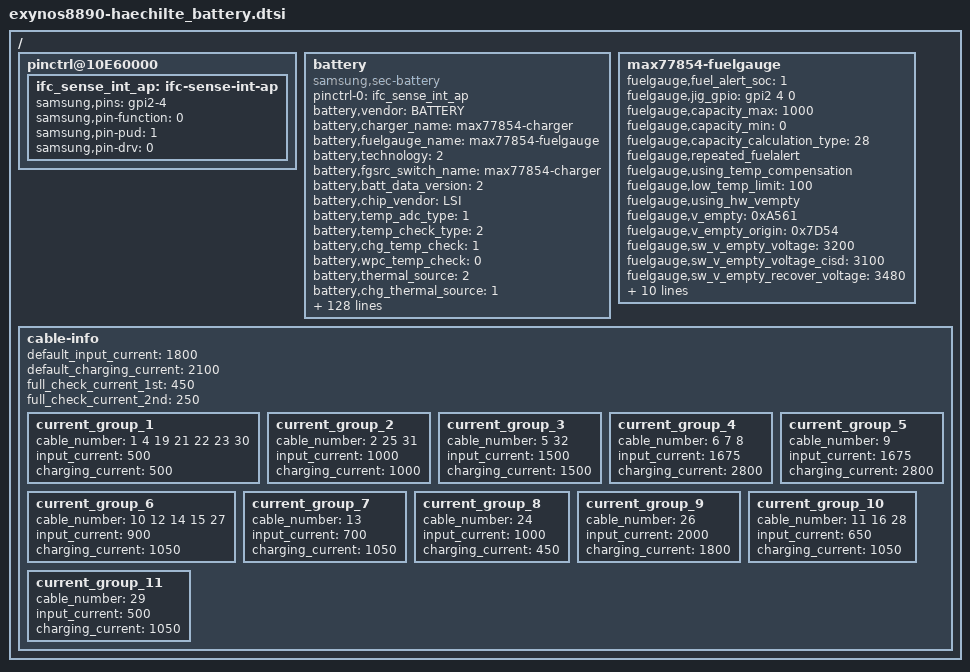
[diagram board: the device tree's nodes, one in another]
/*
 * SAMSUNG UNIVERSAL5433 board device tree source
 *
 * Copyright (c) 2013 Samsung Electronics Co., Ltd.
 *		http://www.samsung.com
 *
 * This program is free software; you can redistribute it and/or modify
 * it under the terms of the GNU General Public License version 2 as
 * published by the Free Software Foundation.
*/

/ {
	pinctrl@10E60000 {

		ifc_sense_int_ap: ifc-sense-int-ap {
			samsung,pins = "gpi2-4";
			samsung,pin-function = <0>;
			samsung,pin-pud = <1>;
			samsung,pin-drv = <0>;
		};
	};
	battery {
		status = "okay";
		compatible = "samsung,sec-battery";

		pinctrl-names = "default";
		pinctrl-0 = <&ifc_sense_int_ap>;
		/* battery,irq_gpio = <&gpa1 6 0>; */

		battery,vendor = "BATTERY";
		battery,charger_name = "max77854-charger";
		battery,fuelgauge_name = "max77854-fuelgauge";
		battery,technology = <2>; /* POWER_SUPPLY_TECHNOLOGY_LION */
		battery,fgsrc_switch_name = "max77854-charger"; /* Fuelgauge voltage source */

		battery,batt_data_version = <2>;

		battery,chip_vendor = "LSI";
		battery,temp_adc_type = <1>; /* SEC_BATTERY_ADC_TYPE_AP */

		battery,temp_check_type = <2>; /* SEC_BATTERY_TEMP_CHECK_TEMP */
		battery,chg_temp_check = <1>;
		battery,wpc_temp_check = <0>;

		battery,thermal_source = <2>; /* SEC_BATTERY_THERMAL_SOURCE_ADC */
		battery,chg_thermal_source = <1>; /* true or false */
		battery,wpc_thermal_source = <0>; /* true or false */
		battery,usb_thermal_source = <0>; /* true or false */
		battery,coil_thermal_source = <0>; /* true or false */

		battery,polling_time = <10 30 30 30 3600>;

		battery,temp_table_adc = <316 359 410 558 611 759 880 1023 1201 1368 1553 1790 2234 2726 2932 3128 3294 3442 3666>;
		battery,temp_table_data = <900 850 800 700 650 600 550 500 450 400 350 300 200 100 50 0 (-50) (-100) (-200)>;

		battery,chg_temp_table_adc = <307 351 405 511 647 758 885 1031 1208 1363 1549 1792 2224 2738 2941 3135 3299 3455 3672>;
		battery,chg_temp_table_data = <900 850 800 700 650 600 550 500 450 400 350 300 200 100 50 0 (-50) (-100) (-200)>;

		battery,wireless_cc_cv = <85>;
		battery,inbat_voltage = <1>;
		battery,inbat_voltage_table_adc = <3120 3101 3061 3038 3001 2956 2920 2887 2856 2814
						2793 2754 2720 2677 2641 2613 2572 2531 2502 2467 2436>;
		battery,inbat_voltage_table_data = <438 435 430 425 420 415 410 405 400 395
						390 385 380 375 370 365 360 355 350 345 340>;

		battery,adc_check_count = <5>;

		battery,cable_check_type = <4>; /* SEC_BATTERY_CABLE_CHECK_PSY */
		battery,cable_source_type = <1>; /* SEC_BATTERY_CABLE_SOURCE_EXTERNAL */
		battery,polling_type = <1>; /* SEC_BATTERY_MONITOR_ALARM */
		battery,monitor_initial_count = <0>;

		battery,battery_check_type = <5>; /* SEC_BATTERY_CHECK_CHARGER */
		battery,check_count = <0>;
		battery,check_adc_max = <1440>;
		battery,check_adc_min = <0>;

		battery,ovp_uvlo_check_type = <3>; /* SEC_BATTERY_OVP_UVLO_CHGPOLLING */

		battery,temp_check_count = <1>;
		battery,temp_highlimit_threshold_event = <800>;
		battery,temp_highlimit_recovery_event = <750>;
		battery,temp_high_threshold_event = <500>;
		battery,temp_high_recovery_event = <450>;
		battery,temp_low_threshold_event = <0>;
		battery,temp_low_recovery_event = <50>;
		battery,temp_highlimit_threshold_normal = <800>;
		battery,temp_highlimit_recovery_normal = <750>;
		battery,temp_high_threshold_normal = <500>;
		battery,temp_high_recovery_normal = <450>;
		battery,temp_low_threshold_normal = <0>;
		battery,temp_low_recovery_normal = <50>;
		battery,temp_highlimit_threshold_lpm = <800>;
		battery,temp_highlimit_recovery_lpm = <750>;
		battery,temp_high_threshold_lpm = <500>;
		battery,temp_high_recovery_lpm = <450>;
		battery,temp_low_threshold_lpm = <0>;
		battery,temp_low_recovery_lpm = <50>;
		battery,full_check_type = <7>; /* SEC_BATTERY_FULLCHARGED_CHGPSY */
		battery,full_check_type_2nd = <7>; /* SEC_BATTERY_FULLCHARGED_CHGPSY */
		battery,full_check_count = <1>;
		battery,chg_gpio_full_check = <0>;
		battery,chg_polarity_full_check = <1>;

		battery,chg_high_temp = <430>; /* EUR use eur_xx.dtsi */
		battery,chg_high_temp_recovery = <380>; /* EUR use eur_xx.dtsi */
		battery,chg_input_limit_current = <1100>;
		battery,chg_charging_limit_current = <2800>;

		battery,sleep_mode_limit_current = <500>;
		battery,wc_full_input_limit_current = <100>;
		battery,wc_cv_current = <820>;

		battery,mix_high_temp = <430>;
		battery,mix_high_chg_temp = <530>;
		battery,mix_high_temp_recovery = <400>;

		/* SEC_BATTERY_FULL_CONDITION_NOTIMEFULL |
		   SEC_BATTERY_FULL_CONDITION_VCELL */
		battery,full_condition_type = <9>;
		battery,full_condition_soc = <93>;
		battery,full_condition_vcell = <4125>;

		battery,recharge_check_count = <1>;
		battery,recharge_condition_type = <4>; /* SEC_BATTERY_RECHARGE_CONDITION_VCELL */
		battery,recharge_condition_soc = <98>;
		battery,recharge_condition_vcell = <4125>;

		battery,charging_total_time = <14400>;
		battery,hv_charging_total_time = <10800>;
		battery,normal_charging_total_time = <18000>;
		battery,usb_charging_total_time = <36000>;
		battery,recharging_total_time = <5400>;
		battery,charging_reset_time = <0>;

		battery,chg_float_voltage = <42250>;
		battery,chg_float_voltage_conv = <10>;

		battery,wa_volt_recov = <4065>;
		battery,wa_volt_thr = <4075>;
		battery,wa_float_voltage = <40500>;

		battery,swelling_high_temp_block = <410>;
		battery,swelling_high_temp_recov = <390>;
		battery,swelling_low_temp_block_1st = <150>;
		battery,swelling_low_temp_recov_1st = <200>;
		battery,swelling_low_temp_block_2nd = <50>;
		battery,swelling_low_temp_recov_2nd = <100>;

		battery,swelling_low_temp_current = <1050>;	/* 0.3C */
		battery,swelling_low_temp_topoff = <250>;	/* 0.05C */
		battery,swelling_high_temp_current = <1600>;	/* 0.45C */
		battery,swelling_high_temp_topoff = <250>;	/* 0.05C */
		battery,swelling_wc_high_temp_current = <1050>;	/* 0.3C */
		battery,swelling_wc_low_temp_current = <1050>;	/* 0.3C */

		battery,swelling_drop_float_voltage = <41000>;
		battery,swelling_high_rechg_voltage = <3900>;
		battery,swelling_low_rechg_voltage = <3900>;

		battery,siop_event_check_type = <1>;
		battery,siop_call_cv_current = <330>;
		battery,siop_call_cc_current = <330>;

		battery,siop_input_limit_current = <1200>;
		battery,siop_charging_limit_current = <1000>;
		battery,siop_hv_input_limit_current = <700>;
		battery,siop_hv_charging_limit_current = <1000>;

		battery,siop_wireless_input_limit_current = <600>;
		battery,siop_wireless_charging_limit_current = <1000>;
		battery,siop_hv_wireless_input_limit_current = <600>;
		battery,siop_hv_wireless_charging_limit_current = <1000>;

		battery,ttf_hv_charge_current = <2800>;
		battery,ttf_hv_wireless_charge_current = <1500>;

		battery,pd_charging_charge_power = <15000>;
		battery,max_charging_current = <2800>;
		battery,battery_full_capacity = <4500>;

		battery,factory_store_mode_max = <70>;
		battery,factory_store_mode_min = <60>;

		/* cycle(week), chg_float_voltage, recharge_condition_vcell, full_condition_vcell, full_condition_soc, max_charging_current(B2B) */
		battery,age_data = <0 42250 4125 4125 93 2800
			70 41875 4087 4087 91 2500
			140 41625 4062 4062 89 2150>;

		battery,max_input_voltage = <12000>; /* mV */
		battery,max_input_current = <3000>;  /* mA */

		battery,enable_sysovlo_irq;

		battery,standard_curr = <2800>;
		battery,expired_time = <13380>;
		battery,recharging_expired_time = <5400>;

		battery,cisd_max_voltage_thr = <4400>; /* battery ovp detection voltage */

		io-channels = <&exynos_adc 1>, <&exynos_adc 3>, <&exynos_adc 6>;
		io-channel-names = "adc-temp", "adc-chg-temp", "adc-in-bat";
		#io-channel-cells = <3>;
		io-channel-ranges;
	};

	max77854-fuelgauge {
		status = "okay";
		fuelgauge,fuel_alert_soc = <1>;
		fuelgauge,jig_gpio = <&gpi2 4 0>;
		fuelgauge,capacity_max = <1000>;

		fuelgauge,capacity_min = <0>;
		fuelgauge,capacity_calculation_type = <28>;
		fuelgauge,repeated_fuelalert;
		fuelgauge,using_temp_compensation;
		fuelgauge,low_temp_limit = <100>;
		fuelgauge,using_hw_vempty;
		fuelgauge,v_empty = <0xA561>; /* Empty: 3260mV, Recover: 3480mV */
		fuelgauge,v_empty_origin = <0x7D54>; /* Empty: 2500mV, Recover: 3360mV */
		fuelgauge,sw_v_empty_voltage = <3200>;
		fuelgauge,sw_v_empty_voltage_cisd = <3100>;
		fuelgauge,sw_v_empty_recover_voltage = <3480>;
		fuelgauge,qrtable20 = <0x0901>;
		fuelgauge,qrtable30 = <0x0803>;
		fuelgauge,dpacc = <0x3200>;
		fuelgauge,dqacc = <0x07BB>;
		fuelgauge,fg_resistor = <1>;
		fuelgauge,capacity = <0x1EED>;
		/*fuelgauge,auto_discharge_en;*/
		fuelgauge,discharge_temp_threshold = <600>;
		fuelgauge,discharge_volt_threshold = <4540>;
		fuelgauge,cv_data = <2480	687	3450
			2462	693	3420
			2442	699	3389
			2421	704	3360
			2401	710	3329
			2379	715	3300
			2357	721	3269
			2338	726	3240
			2316	731	3209
			2294	737	3181
			2272	742	3150
			2248	747	3121
			2225	752	3090
			2202	757	3060
			2180	762	3029
			2156	767	3000
			2133	772	2969
			2132	773	2940
			2110	777	2909
			2086	782	2905
			2064	786	2881
			2035	791	2850
			2016	795	2820
			1991	800	2789
			1967	802	2760
			1945	804	2729
			1919	808	2700
			1895	812	2669
			1873	817	2640
			1850	821	2609
			1826	825	2581
			1801	829	2550
			1781	833	2520
			1759	837	2489
			1738	841	2460
			1716	844	2429
			1695	848	2401
			1672	852	2370
			1650	856	2340
			1628	859	2309
			1607	863	2280
			1585	866	2249
			1565	870	2220
			1543	873	2189
			1520	875	2160
			1498	877	2129
			1475	880	2099
			1455	882	2068
			1450	884	2040
			1409	887	2009
			1383	891	1981
			1360	893	1950
			1336	896	1920
			1313	899	1889
			1290	902	1860
			1279	905	1829
			1228	908	1800
			1205	911	1769
			1185	913	1740
			1162	916	1709
			1140	918	1680
			1118	921	1649
			1098	923	1620
			1077	926	1589
			1059	928	1560
			1041	930	1529
			1024	931	1501
			1006	933	1470
			990	935	1439
			975	937	1409
			960	939	1380
			946	940	1349
			931	941	1321
			914	943	1290
			903	945	1260
			895	946	1229
			876	947	1199
			867	949	1168
			866	950	1140
			851	951	1109
			837	953	1105
			826	955	1079
			814	957	1048
			800	959	1021
			787	961	990
			775	962	960
			762	963	929
			749	965	900
			738	966	869
			725	968	840
			714	969	809
			702	970	781
			692	971	750
			680	972	720
			669	973	689
			656	975	660
			646	977	629
			636	978	601
			621	980	570
			613	981	540
			605	982	509
			600	983	480
			597	984	449
			581	985	420
			547	986	389
			540	988	360
			532	989	329
			523	990	301
			517	991	270
			515	992	241
			508	993	210
			501	994	180
			491	995	149
			483	996	121
			473	998	90
			465	997	61
			457	999	30
			0	1000	0>;
	};

/* sec_battery_cable
 *   0	UNKNOWN,
 *   1	NONE,
 *   2	PREPARE_TA,
 *   3	TA,
 *   4	USB,
 *   5	USB_CDP,
 *   6	9V_TA,
 *   7	9V_ERR,
 *   8	9V_UNKNOWN,
 *   9	12V_TA,
 *  10	WIRELESS,
 *  11	HV_WIRELESS,
 *  12	PMA_WIRELESS,
 *  13	WIRELESS_PACK,
 *  14	WIRELESS_PACK_TA,
 *  15	WIRELESS_STAND,
 *  16	WIRELESS_HV_STAND,
 *  17	QC20,
 *  18	QC30,
 *  19	PDIC,
 *  20	UARTOFF,
 *  21	OTG,
 *  22	LAN_HUB,
 *  23	POWER_SHARING,
 *  24	HMT_CONNECTED,
 *  25	HMT_CHARGE,
 *  26	HV_TA_CHG_LIMIT,
 *  27	WIRELESS_VEHICLE,
 *  28	WIRELESS_HV_VEHICLE,
 *  29	PREPARE_WIRELESS_HV,
 *  30	TIMEOUT,
 *  31  SMART_OTG,
 *  32  SMART_NOTG,
 *  33	CABLE_MAX,
*/
	cable-info {
		   default_input_current = <1800>;
		   default_charging_current = <2100>;
		   full_check_current_1st = <450>;
		   full_check_current_2nd = <250>;

		   current_group_1 {
		   	       cable_number = <1 4 19 21 22 23 30>;
			       input_current = <500>;
			       charging_current = <500>;
		   };
		   current_group_2 {
		   	       cable_number = <2 25 31>;
			       input_current = <1000>;
			       charging_current = <1000>;
		  };
		   current_group_3 {
		   	       cable_number = <5 32>;
			       input_current = <1500>;
			       charging_current = <1500>;
		  };
		   current_group_4 {
		   	       cable_number = <6 7 8>;
			       input_current = <1675>;
			       charging_current = <2800>;
		  };
		   current_group_5 {
		   	       cable_number = <9>;
			       input_current = <1675>;
			       charging_current = <2800>;
		  };
		   current_group_6 {
		   	       cable_number = <10 12 14 15 27>;
			       input_current = <900>;
			       charging_current = <1050>;
		  };
		   current_group_7 {
		   	       cable_number = <13>;
			       input_current = <700>;
			       charging_current = <1050>;
		  };
		   current_group_8 {
		   	       cable_number = <24>;
			       input_current = <1000>;
			       charging_current = <450>;
		  };
		   current_group_9 {
		   	       cable_number = <26>;
			       input_current = <2000>;
			       charging_current = <1800>;
		  };
		   current_group_10 {
		   	       cable_number = <11 16 28>;
			       input_current = <650>;
			       charging_current = <1050>;
		  };
		   current_group_11 {
		   	       cable_number = <29>;
			       input_current = <500>;
			       charging_current = <1050>;
		  };
	};
};
